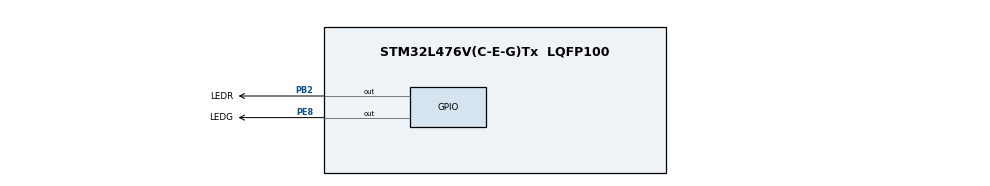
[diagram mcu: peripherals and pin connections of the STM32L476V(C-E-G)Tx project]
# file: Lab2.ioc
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Mcu.Family=STM32L4
Mcu.Name=STM32L476V(C-E-G)Tx
Mcu.Package=LQFP100
NVIC.PriorityGroup=NVIC_PRIORITYGROUP_4
NVIC.RNG_IRQn=true\:0\:0\:false\:false\:true\:true\:true
NVIC.TIM3_IRQn=true\:0\:0\:false\:false\:true\:true\:true
NVIC.TIM4_IRQn=true\:0\:0\:false\:false\:true\:true\:true
PB2.GPIO_Label=LEDR
PB2.Signal=GPIO_Output
PE8.GPIO_Label=LEDG
PE8.Signal=GPIO_Output
ProjectManager.HeapSize=0x200
ProjectManager.StackSize=0x400
ProjectManager.TargetToolchain=MDK-ARM V5.27
RCC.ADCFreq_Value=32000000
RCC.CortexFreq_Value=4000000
RCC.HSE_VALUE=8000000
RCC.HSI_VALUE=16000000
RCC.LSE_VALUE=32768
RCC.MSI_VALUE=4000000
RCC.PLLSAI1N=16
RCC.PREFETCH_ENABLE=1
RCC.USBFreq_Value=32000000
RCC.VCOOutputFreq_Value=32000000
TIM3.AutoReloadPreload=TIM_AUTORELOAD_PRELOAD_ENABLE
TIM3.Period=4999
TIM3.Prescaler=399
TIM4.AutoReloadPreload=TIM_AUTORELOAD_PRELOAD_ENABLE
TIM4.Channel-Output\ Compare1\ No\ Output=TIM_CHANNEL_1
TIM4.OC1Preload=ENABLE
TIM4.Prescaler=399
TIM4.Pulse-Output\ Compare1\ No\ Output=9999
VP_RNG_VS_RNG.Mode=RNG_Activate
VP_TIM3_VS_ClockSourceINT.Mode=Internal
VP_TIM4_VS_ClockSourceINT.Mode=Internal
VP_TIM4_VS_no_output1.Mode=Output Compare1 No Output
board=STM32L476G-DISCO

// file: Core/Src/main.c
/* USER CODE BEGIN Header */
/**
  ******************************************************************************
  * @file           : main.c
  * @brief          : Main program body
  ******************************************************************************
  * @attention
  *
  * <h2><center>&copy; Copyright (c) 2020 STMicroelectronics.
  * All rights reserved.</center></h2>
  *
  * This software component is licensed by ST under BSD 3-Clause license,
  * the "License"; You may not use this file except in compliance with the
  * License. You may obtain a copy of the License at:
  *                        opensource.org/licenses/BSD-3-Clause
  *
  ******************************************************************************
  */
/* USER CODE END Header */
#include "main.h"

/* USER CODE BEGIN Includes */
#include "eeprom.h"
/* USER CODE END Includes */

RNG_HandleTypeDef hrng;

TIM_HandleTypeDef htim3;
TIM_HandleTypeDef htim4;

/* USER CODE BEGIN PV */
uint16_t VirtAddVarTab[NB_OF_VAR] = {0x5555, 0x6666, 0x7777};
uint16_t counter = 0;
uint32_t random=0;
char lcd_buffer[6];
/* USER CODE END PV */

void SystemClock_Config(void);
static void MX_GPIO_Init(void);
static void MX_TIM3_Init(void);
static void MX_TIM4_Init(void);
static void MX_RNG_Init(void);

/* USER CODE BEGIN 0 */
uint16_t best=0;
/* USER CODE END 0 */

int main(void)
{

  /* MCU Configuration--------------------------------------------------------*/

  /* Reset of all peripherals, Initializes the Flash interface and the Systick. */
  HAL_Init();

  /* USER CODE BEGIN Init */
	BSP_LCD_GLASS_Init();
	BSP_JOY_Init(JOY_MODE_EXTI);
	BSP_LED_Init(LED5);
	EE_Init();
	MX_RNG_Init();
  /* USER CODE END Init */

  /* Configure the system clock */
  SystemClock_Config();

  /* Initialize all configured peripherals */
  MX_GPIO_Init();
  MX_TIM3_Init();
  MX_TIM4_Init();
  MX_RNG_Init();
  /* USER CODE BEGIN 2 */
	HAL_FLASH_Unlock();
	EE_WriteVariable(VirtAddVarTab[0],9999);

	BSP_LCD_GLASS_Clear();
	BSP_LCD_GLASS_DisplayString((uint8_t*)"Ready");
  /* USER CODE END 2 */

  /* Infinite loop */
  while (1)
  {

  }
}

void SystemClock_Config(void)
{
  RCC_OscInitTypeDef RCC_OscInitStruct = {0};
  RCC_ClkInitTypeDef RCC_ClkInitStruct = {0};
  RCC_PeriphCLKInitTypeDef PeriphClkInit = {0};

  /** Initializes the RCC Oscillators according to the specified parameters
  * in the RCC_OscInitTypeDef structure.
  */
  RCC_OscInitStruct.OscillatorType = RCC_OSCILLATORTYPE_MSI;
  RCC_OscInitStruct.MSIState = RCC_MSI_ON;
  RCC_OscInitStruct.MSICalibrationValue = 0;
  RCC_OscInitStruct.MSIClockRange = RCC_MSIRANGE_6;
  RCC_OscInitStruct.PLL.PLLState = RCC_PLL_NONE;
  if (HAL_RCC_OscConfig(&RCC_OscInitStruct) != HAL_OK)
  {
    Error_Handler();
  }
  /** Initializes the CPU, AHB and APB buses clocks
  */
  RCC_ClkInitStruct.ClockType = RCC_CLOCKTYPE_HCLK|RCC_CLOCKTYPE_SYSCLK
                              |RCC_CLOCKTYPE_PCLK1|RCC_CLOCKTYPE_PCLK2;
  RCC_ClkInitStruct.SYSCLKSource = RCC_SYSCLKSOURCE_MSI;
  RCC_ClkInitStruct.AHBCLKDivider = RCC_SYSCLK_DIV1;
  RCC_ClkInitStruct.APB1CLKDivider = RCC_HCLK_DIV1;
  RCC_ClkInitStruct.APB2CLKDivider = RCC_HCLK_DIV1;

  if (HAL_RCC_ClockConfig(&RCC_ClkInitStruct, FLASH_LATENCY_0) != HAL_OK)
  {
    Error_Handler();
  }
  PeriphClkInit.PeriphClockSelection = RCC_PERIPHCLK_RNG;
  PeriphClkInit.RngClockSelection = RCC_RNGCLKSOURCE_PLLSAI1;
  PeriphClkInit.PLLSAI1.PLLSAI1Source = RCC_PLLSOURCE_MSI;
  PeriphClkInit.PLLSAI1.PLLSAI1M = 1;
  PeriphClkInit.PLLSAI1.PLLSAI1N = 8;
  PeriphClkInit.PLLSAI1.PLLSAI1P = RCC_PLLP_DIV7;
  PeriphClkInit.PLLSAI1.PLLSAI1Q = RCC_PLLQ_DIV2;
  PeriphClkInit.PLLSAI1.PLLSAI1R = RCC_PLLR_DIV2;
  PeriphClkInit.PLLSAI1.PLLSAI1ClockOut = RCC_PLLSAI1_48M2CLK;
  if (HAL_RCCEx_PeriphCLKConfig(&PeriphClkInit) != HAL_OK)
  {
    Error_Handler();
  }
  /** Configure the main internal regulator output voltage
  */
  if (HAL_PWREx_ControlVoltageScaling(PWR_REGULATOR_VOLTAGE_SCALE1) != HAL_OK)
  {
    Error_Handler();
  }
}

static void MX_RNG_Init(void)
{

  hrng.Instance = RNG;
  if (HAL_RNG_Init(&hrng) != HAL_OK)
  {
    Error_Handler();
  }

}

static void MX_TIM3_Init(void)
{

  TIM_ClockConfigTypeDef sClockSourceConfig = {0};
  TIM_MasterConfigTypeDef sMasterConfig = {0};

  htim3.Instance = TIM3;
  htim3.Init.Prescaler = 399;
  htim3.Init.CounterMode = TIM_COUNTERMODE_UP;
  htim3.Init.Period = 9;
  htim3.Init.ClockDivision = TIM_CLOCKDIVISION_DIV1;
  htim3.Init.AutoReloadPreload = TIM_AUTORELOAD_PRELOAD_ENABLE;
  if (HAL_TIM_Base_Init(&htim3) != HAL_OK)
  {
    Error_Handler();
  }
  sClockSourceConfig.ClockSource = TIM_CLOCKSOURCE_INTERNAL;
  if (HAL_TIM_ConfigClockSource(&htim3, &sClockSourceConfig) != HAL_OK)
  {
    Error_Handler();
  }
  sMasterConfig.MasterOutputTrigger = TIM_TRGO_RESET;
  sMasterConfig.MasterSlaveMode = TIM_MASTERSLAVEMODE_DISABLE;
  if (HAL_TIMEx_MasterConfigSynchronization(&htim3, &sMasterConfig) != HAL_OK)
  {
    Error_Handler();
  }
  /* USER CODE BEGIN TIM3_Init 2 */
if (HAL_TIM_Base_Start_IT(&htim3) != HAL_OK)
	{
		Error_Handler();
	}
  /* USER CODE END TIM3_Init 2 */

}

static void MX_TIM4_Init(void)
{

  TIM_ClockConfigTypeDef sClockSourceConfig = {0};
  TIM_MasterConfigTypeDef sMasterConfig = {0};
  TIM_OC_InitTypeDef sConfigOC = {0};

  htim4.Instance = TIM4;
  htim4.Init.Prescaler = 3999;
  htim4.Init.CounterMode = TIM_COUNTERMODE_UP;
  htim4.Init.Period = 999;
  htim4.Init.ClockDivision = TIM_CLOCKDIVISION_DIV1;
  htim4.Init.AutoReloadPreload = TIM_AUTORELOAD_PRELOAD_ENABLE;
  if (HAL_TIM_Base_Init(&htim4) != HAL_OK)
  {
    Error_Handler();
  }
  sClockSourceConfig.ClockSource = TIM_CLOCKSOURCE_INTERNAL;
  if (HAL_TIM_ConfigClockSource(&htim4, &sClockSourceConfig) != HAL_OK)
  {
    Error_Handler();
  }
  if (HAL_TIM_OC_Init(&htim4) != HAL_OK)
  {
    Error_Handler();
  }
  sMasterConfig.MasterOutputTrigger = TIM_TRGO_RESET;
  sMasterConfig.MasterSlaveMode = TIM_MASTERSLAVEMODE_DISABLE;
  if (HAL_TIMEx_MasterConfigSynchronization(&htim4, &sMasterConfig) != HAL_OK)
  {
    Error_Handler();
  }
  sConfigOC.OCMode = TIM_OCMODE_TIMING;
  sConfigOC.Pulse = 9999;
  sConfigOC.OCPolarity = TIM_OCPOLARITY_HIGH;
  sConfigOC.OCFastMode = TIM_OCFAST_DISABLE;
  if (HAL_TIM_OC_ConfigChannel(&htim4, &sConfigOC, TIM_CHANNEL_1) != HAL_OK)
  {
    Error_Handler();
  }
  __HAL_TIM_ENABLE_OCxPRELOAD(&htim4, TIM_CHANNEL_1);
  /* USER CODE BEGIN TIM4_Init 2 */
if (HAL_TIM_OC_Start_IT(&htim4, TIM_CHANNEL_2) != HAL_OK)
	{
		Error_Handler();
	}
  /* USER CODE END TIM4_Init 2 */

}

static void MX_GPIO_Init(void)
{
  GPIO_InitTypeDef GPIO_InitStruct = {0};

  /* GPIO Ports Clock Enable */
  __HAL_RCC_GPIOB_CLK_ENABLE();
  __HAL_RCC_GPIOE_CLK_ENABLE();

  /*Configure GPIO pin Output Level */
  HAL_GPIO_WritePin(LEDR_GPIO_Port, LEDR_Pin, GPIO_PIN_RESET);

  /*Configure GPIO pin Output Level */
  HAL_GPIO_WritePin(LEDG_GPIO_Port, LEDG_Pin, GPIO_PIN_RESET);

  /*Configure GPIO pin : LEDR_Pin */
  GPIO_InitStruct.Pin = LEDR_Pin;
  GPIO_InitStruct.Mode = GPIO_MODE_OUTPUT_PP;
  GPIO_InitStruct.Pull = GPIO_NOPULL;
  GPIO_InitStruct.Speed = GPIO_SPEED_FREQ_LOW;
  HAL_GPIO_Init(LEDR_GPIO_Port, &GPIO_InitStruct);

  /*Configure GPIO pin : LEDG_Pin */
  GPIO_InitStruct.Pin = LEDG_Pin;
  GPIO_InitStruct.Mode = GPIO_MODE_OUTPUT_PP;
  GPIO_InitStruct.Pull = GPIO_NOPULL;
  GPIO_InitStruct.Speed = GPIO_SPEED_FREQ_LOW;
  HAL_GPIO_Init(LEDG_GPIO_Port, &GPIO_InitStruct);

}

/* USER CODE BEGIN 4 */
void HAL_TIM_PeriodElapsedCallback(TIM_HandleTypeDef *htim)
{
	if ((*htim).Instance==TIM3)
		counter++;
		//BSP_LED_Toggle(LED4);
		//HAL_GPIO_TogglePin(GPIOE,GPIO_PIN_8);
}

void HAL_TIM_OC_DelayElapsedCallback(TIM_HandleTypeDef * htim)
{
	//HAL_GPIO_TogglePin(LEDG_GPIO_Port, LEDG_Pin);
	BSP_LED_Toggle(LED5);
	__HAL_TIM_SET_COUNTER(htim, 0x0000);
}

void HAL_GPIO_EXTI_Callback(uint16_t GPIO_Pin)
{

	//Entering State 2
	if (GPIO_Pin == GPIO_PIN_1)
	{
		NVIC_DisableIRQ(TIM4_IRQn);
		BSP_LED_Off(LED5);
		random = (HAL_RNG_GetRandomNumber(&hrng));
		random = (random%10)*400;
		counter = 0;
		while(counter < random)
		{
			BSP_LCD_GLASS_DisplayString((uint8_t*)"HOLD");
		}
		BSP_LCD_GLASS_DisplayString((uint8_t*)"PRESS");

		//Entering State 3
		NVIC_EnableIRQ(TIM4_IRQn);
		BSP_LED_On(LED5);
		counter = 0;
	}

	//Entering State 4
	if (GPIO_Pin == GPIO_PIN_2 && counter!=0)
	{
		sprintf(lcd_buffer, "%d", counter);
		BSP_LCD_GLASS_Clear();
		BSP_LCD_GLASS_DisplayString((uint8_t*)lcd_buffer);
		EE_ReadVariable(VirtAddVarTab[0],&best);

		//Entering State 5
		if(counter < best)
		{
			EE_WriteVariable(VirtAddVarTab[0], counter);
		}
	}

	//Anti Cheat Method
	if (GPIO_Pin == GPIO_PIN_2 && counter == 0)
	{
		BSP_LCD_GLASS_Clear();
		BSP_LCD_GLASS_DisplayString((uint8_t*)"CHEAT");
		HAL_Delay(5000);
	}

	//Entering State 6
	if (GPIO_Pin == GPIO_PIN_5)
	{
		EE_ReadVariable(VirtAddVarTab[0],&best);
		BSP_LCD_GLASS_Clear();
		BSP_LCD_GLASS_DisplayString((uint8_t*)best);
	}
}
/* USER CODE END 4 */

void Error_Handler(void)
{
}

/************************ (C) COPYRIGHT STMicroelectronics *****END OF FILE****/
